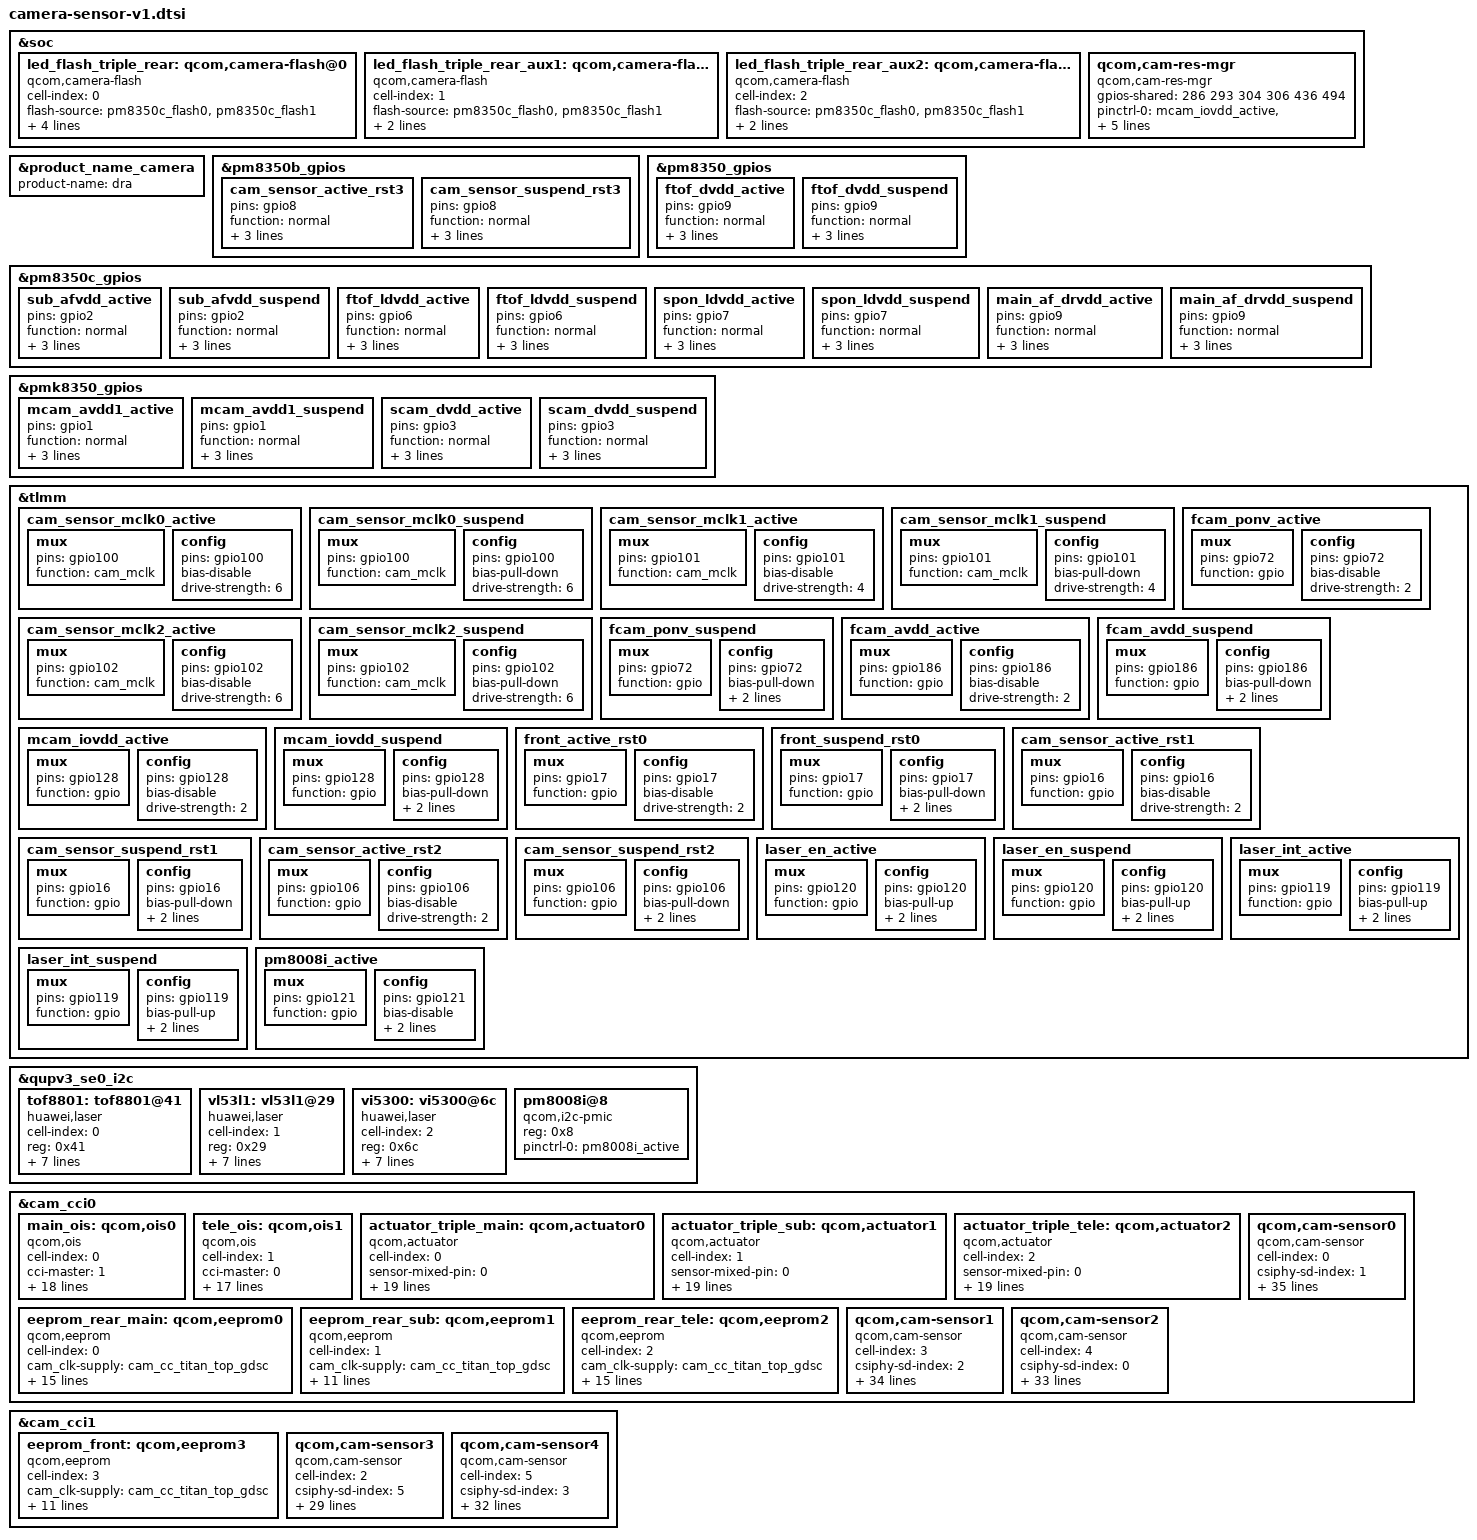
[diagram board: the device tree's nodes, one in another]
#include <dt-bindings/clock/qcom,camcc-lahaina.h>

&soc {
	led_flash_triple_rear: qcom,camera-flash@0 {
		cell-index = <0>;
		compatible = "qcom,camera-flash";
		flash-source = <&pm8350c_flash0 &pm8350c_flash1>;
		torch-source = <&pm8350c_torch0 &pm8350c_torch1>;
		switch-source = <&pm8350c_switch2>;
		torch-light-num = <0 1>;
		torch-light-name = "torch-light0", "torch-light1";
		status = "ok";
	};

	led_flash_triple_rear_aux1: qcom,camera-flash@1 {
		cell-index = <1>;
		compatible = "qcom,camera-flash";
		flash-source = <&pm8350c_flash0 &pm8350c_flash1>;
		torch-source = <&pm8350c_torch0 &pm8350c_torch1>;
		switch-source = <&pm8350c_switch2>;
		status = "ok";
	};

	led_flash_triple_rear_aux2: qcom,camera-flash@2 {
		cell-index = <2>;
		compatible = "qcom,camera-flash";
		flash-source = <&pm8350c_flash0 &pm8350c_flash1>;
		torch-source = <&pm8350c_torch0 &pm8350c_torch1>;
		switch-source = <&pm8350c_switch2>;
		status = "ok";
	};

	qcom,cam-res-mgr {
		compatible = "qcom,cam-res-mgr";
		status = "ok";
		gpios-shared = <286 293 304 306 436 494>;
		pinctrl-names = "cam_active", "cam_suspend";
		pinctrl-0 = <&mcam_iovdd_active
					&front_active_rst0
					&fcam_avdd_active
					&mcam_avdd1_active>;
		pinctrl-1 = <&mcam_iovdd_suspend
					&front_suspend_rst0
					&fcam_avdd_suspend
					&mcam_avdd1_suspend>;
	};
};

&product_name_camera {
    product-name = "dra";
};

&pm8350b_gpios {
	cam_sensor_active_rst3: cam_sensor_active_rst3 {
		pins = "gpio8";
		function = "normal";
		bias-disable;
		output-high;
		power-source = <0>;
	};
	cam_sensor_suspend_rst3: cam_sensor_suspend_rst3 {
		pins = "gpio8";
		function = "normal";
		bias-disable;
		output-low;
		power-source = <0>;
	};
};

&pm8350_gpios {
	ftof_dvdd_active: ftof_dvdd_active {
		pins = "gpio9";
		function = "normal";
		bias-disable;
		output-high;
		power-source = <0>;
	};
	ftof_dvdd_suspend: ftof_dvdd_suspend {
		pins = "gpio9";
		function = "normal";
		bias-disable;
		output-low;
		power-source = <0>;
	};
};

&pm8350c_gpios {
	sub_afvdd_active: sub_afvdd_active {
		pins = "gpio2";
		function = "normal";
		bias-disable;
		output-high;
		power-source = <0>;
	};
	sub_afvdd_suspend: sub_afvdd_suspend {
		pins = "gpio2";
		function = "normal";
		bias-disable;
		output-low;
		power-source = <0>;
	};
	ftof_ldvdd_active: ftof_ldvdd_active {
		pins = "gpio6";
		function = "normal";
		bias-disable;
		output-high;
		power-source = <0>;
	};
	ftof_ldvdd_suspend: ftof_ldvdd_suspend {
		pins = "gpio6";
		function = "normal";
		bias-disable;
		output-low;
		power-source = <0>;
	};
	spon_ldvdd_active: spon_ldvdd_active {
		pins = "gpio7";
		function = "normal";
		bias-disable;
		output-high;
		power-source = <0>;
	};
	spon_ldvdd_suspend: spon_ldvdd_suspend {
		pins = "gpio7";
		function = "normal";
		bias-disable;
		output-low;
		power-source = <0>;
	};
	main_af_drvdd_active: main_af_drvdd_active {
		pins = "gpio9";
		function = "normal";
		bias-disable;
		output-high;
		power-source = <0>;
	};
	main_af_drvdd_suspend: main_af_drvdd_suspend {
		pins = "gpio9";
		function = "normal";
		bias-disable;
		output-low;
		power-source = <0>;
	};
};

&pmk8350_gpios {
	mcam_avdd1_active: mcam_avdd1_active {
		pins = "gpio1";
		function = "normal";
		bias-disable;
		output-high;
		power-source = <0>;
	};
	mcam_avdd1_suspend: mcam_avdd1_suspend {
		pins = "gpio1";
		function = "normal";
		bias-disable;
		output-low;
		power-source = <0>;
	};

	scam_dvdd_active: scam_dvdd_active {
		pins = "gpio3";
		function = "normal";
		bias-disable;
		output-high;
		power-source = <0>;
	};
	scam_dvdd_suspend: scam_dvdd_suspend {
		pins = "gpio3";
		function = "normal";
		bias-disable;
		output-low;
		power-source = <0>;
	};
};

&tlmm {
	cam_sensor_mclk0_active: cam_sensor_mclk0_active {
		/* MCLK0 */
		mux {
			pins = "gpio100";
			function = "cam_mclk";
		};

		config {
			pins = "gpio100";
			bias-disable; /* No PULL */
			drive-strength = <6>; /* 2 MA */
		};
	};

	cam_sensor_mclk0_suspend: cam_sensor_mclk0_suspend {
		/* MCLK0 */
		mux {
			pins = "gpio100";
			function = "cam_mclk";
		};

		config {
			pins = "gpio100";
			bias-pull-down; /* PULL DOWN */
			drive-strength = <6>; /* 2 MA */
		};
	};

	cam_sensor_mclk1_active: cam_sensor_mclk1_active {
		/* MCLK1 */
		mux {
			pins = "gpio101";
			function = "cam_mclk";
		};

		config {
			pins = "gpio101";
			bias-disable; /* No PULL */
			drive-strength = <4>; /* 2 MA */
		};
	};

	cam_sensor_mclk1_suspend: cam_sensor_mclk1_suspend {
		/* MCLK1 */
		mux {
			pins = "gpio101";
			function = "cam_mclk";
		};

		config {
			pins = "gpio101";
			bias-pull-down; /* PULL DOWN */
			drive-strength = <4>; /* 2 MA */
		};
	};

	cam_sensor_mclk2_active: cam_sensor_mclk2_active {
		/* MCLK2 */
		mux {
			pins = "gpio102";
			function = "cam_mclk";
		};

		config {
			pins = "gpio102";
			bias-disable; /* No PULL */
			drive-strength = <6>; /* 2 MA */
		};
	};

	cam_sensor_mclk2_suspend: cam_sensor_mclk2_suspend {
		/* MCLK2 */
		mux {
			pins = "gpio102";
			function = "cam_mclk";
		};

		config {
			pins = "gpio102";
			bias-pull-down; /* PULL DOWN */
			drive-strength = <6>; /* 2 MA */
		};
	};

	fcam_ponv_active: fcam_ponv_active {
		/* fcam ponv */
		mux {
			pins = "gpio72";
			function = "gpio";
		};

		config {
			pins = "gpio72";
			bias-disable; /* No PULL */
			drive-strength = <2>; /* 2 MA */
		};
	};

	fcam_ponv_suspend: fcam_ponv_suspend {
		/* fcam ponv */
		mux {
			pins = "gpio72";
			function = "gpio";
		};

		config {
			pins = "gpio72";
			bias-pull-down; /* PULL DOWN */
			drive-strength = <2>; /* 2 MA */
			output-low;
		};
	};

	fcam_avdd_active: fcam_avdd_active {
		/* fcam avdd */
		mux {
			pins = "gpio186";
			function = "gpio";
		};

		config {
			pins = "gpio186";
			bias-disable; /* No PULL */
			drive-strength = <2>; /* 2 MA */
		};
	};
	fcam_avdd_suspend: fcam_avdd_suspend {
		/* fcam avdd */
		mux {
			pins = "gpio186";
			function = "gpio";
		};

		config {
			pins = "gpio186";
			bias-pull-down; /* PULL DOWN */
			drive-strength = <2>; /* 2 MA */
			output-low;
		};
	};

	mcam_iovdd_active: mcam_iovdd_active {
		mux {
			pins = "gpio128";
			function = "gpio";
		};

		config {
			pins = "gpio128";
			bias-disable; /* No PULL */
			drive-strength = <2>; /* 2 MA */
		};
	};
	mcam_iovdd_suspend: mcam_iovdd_suspend {
		mux {
			pins = "gpio128";
			function = "gpio";
		};

		config {
			pins = "gpio128";
			bias-pull-down; /* PULL DOWN */
			drive-strength = <2>; /* 2 MA */
			output-low;
		};
	};

	front_active_rst0: front_active_rst0 {
		/* RESET 0 */
		mux {
			pins = "gpio17";
			function = "gpio";
		};

		config {
			pins = "gpio17";
			bias-disable; /* No PULL */
			drive-strength = <2>; /* 2 MA */
		};
	};

	front_suspend_rst0: front_suspend_rst0 {
		/* RESET 0 */
		mux {
			pins = "gpio17";
			function = "gpio";
		};

		config {
			pins = "gpio17";
			bias-pull-down; /* PULL DOWN */
			drive-strength = <2>; /* 2 MA */
			output-low;
		};
	};

	cam_sensor_active_rst1: cam_sensor_active_rst1 {
		/* RESET 1 */
		mux {
			pins = "gpio16";
			function = "gpio";
		};

		config {
			pins = "gpio16";
			bias-disable; /* No PULL */
			drive-strength = <2>; /* 2 MA */
		};
	};
	cam_sensor_suspend_rst1: cam_sensor_suspend_rst1 {
		/* RESET 1 */
		mux {
			pins = "gpio16";
			function = "gpio";
		};

		config {
			pins = "gpio16";
			bias-pull-down; /* PULL DOWN */
			drive-strength = <2>; /* 2 MA */
			output-low;
		};
	};

	cam_sensor_active_rst2: cam_sensor_active_rst2 {
		/* RESET 2 */
		mux {
			pins = "gpio106";
			function = "gpio";
		};

		config {
			pins = "gpio106";
			bias-disable; /* No PULL */
			drive-strength = <2>; /* 2 MA */
		};
	};
	cam_sensor_suspend_rst2: cam_sensor_suspend_rst2 {
		/* RESET 2 */
		mux {
			pins = "gpio106";
			function = "gpio";
		};

		config {
			pins = "gpio106";
			bias-pull-down; /* PULL DOWN */
			drive-strength = <2>; /* 2 MA */
			output-low;
		};
	};

	laser_en_active: laser_en_active {
		/* laser en pin */
		mux {
			pins = "gpio120";
			function = "gpio";
		};

		config {
			pins = "gpio120";
			bias-pull-up; /* PULL UP */
			drive-strength = <2>; /* 2 MA */
			input-enable;
		};
	};

	laser_en_suspend: laser_en_suspend {
		/* laser en pin */
		mux {
			pins = "gpio120";
			function = "gpio";
		};

		config {
			pins = "gpio120";
			bias-pull-up; /* PULL UP */
			drive-strength = <2>; /* 2 MA */
			input-enable;
		};
	};

	laser_int_active: laser_int_active {
		/* laser int pin */
		mux {
			pins = "gpio119";
			function = "gpio";
		};

		config {
			pins = "gpio119";
			bias-pull-up; /* PULL UP */
			drive-strength = <2>; /* 2 MA */
			input-enable;
		};
	};

	laser_int_suspend: laser_int_suspend {
		/* laser int pin */
		mux {
			pins = "gpio119";
			function = "gpio";
		};

		config {
			pins = "gpio119";
			bias-pull-up; /* PULL UP */
			drive-strength = <2>; /* 2 MA */
			input-enable;
		};
	};

	pm8008i_active: pm8008i_active {
		mux {
			pins = "gpio121";
			function = "gpio";
		};

		config {
			pins = "gpio121";
			bias-disable;
			output-low;
			drive-strength = <2>;
		};
	};
};

/* laser */
&qupv3_se0_i2c {
	status = "ok";
	#address-cells = <1>;
	#size-cells = <0>;

	tof8801: tof8801@41 {
		cell-index = <0>;
		compatible = "huawei,laser";
		reg = <0x41>;
		vdd_ana-supply = <&pm8350_l7>;
		gpios = <&tlmm 120 0>,
			<&tlmm 119 0>;
		pinctrl-names = "laser_int_active", "laser_en_active";
		pinctrl-0 = <&laser_int_active>;
		pinctrl-1 = <&laser_en_active>;
		gpio-req-tbl-num = <0>;
		gpio-req-tbl-flags = <0>;
		gpio-req-tbl-label = "CAM_VAF0";
		status = "ok";
	};

	vl53l1: vl53l1@29 {
		cell-index = <1>;
		compatible = "huawei,laser";
		reg = <0x29>;
		vdd_ana-supply = <&pm8350_l7>;
		gpios = <&tlmm 120 0>,
			<&tlmm 119 0>;
		pinctrl-names = "laser_int_active", "laser_en_active";
		pinctrl-0 = <&laser_int_active>;
		pinctrl-1 = <&laser_en_active>;
		gpio-req-tbl-num = <0>;
		gpio-req-tbl-flags = <0>;
		gpio-req-tbl-label = "CAM_VAF0";
		status = "ok";
	};

	vi5300: vi5300@6c {
		cell-index = <2>;
		compatible = "huawei,laser";
		reg = <0x6c>;
		vdd_ana-supply = <&pm8350_l7>;
		gpios = <&tlmm 120 0>,
			<&tlmm 119 0>;
		pinctrl-names = "laser_int_active", "laser_en_active";
		pinctrl-0 = <&laser_int_active>;
		pinctrl-1 = <&laser_en_active>;
		gpio-req-tbl-num = <0>;
		gpio-req-tbl-flags = <0>;
		gpio-req-tbl-label = "CAM_VAF0";
		status = "ok";
	};

	pm8008i@8 {
		compatible = "qcom,i2c-pmic";
		reg = <0x8>;
		#address-cells = <1>;
		#size-cells = <0>;

		pinctrl-names = "default";
		pinctrl-0 = <&pm8008i_active>;

	};
};

&cam_cci0 {
	main_ois: qcom,ois0 {
		cell-index = <0>;
		compatible = "qcom,ois";
		cci-master = <1>;
		cam_clk-supply = <&cam_cc_titan_top_gdsc>;
		regulator-names = "cam_clk";
		rgltr-cntrl-support;
		rgltr-min-voltage = <0>;
		rgltr-max-voltage = <0>;
		rgltr-load-current = <0>;
		gpio-no-mux = <0>;
		pinctrl-names = "cam_default", "cam_suspend";
		pinctrl-0 = <&main_af_drvdd_active>;
		pinctrl-1 = <&main_af_drvdd_suspend>;
		gpios = <&pm8350c_gpios 9 0>,
			<&tlmm 121 0>;
		gpio-mixed1 = <0>;
		gpio-mixed2 = <1>;
		gpio-req-tbl-num = <0 1>;
		gpio-req-tbl-flags = <0 0>;
		gpio-req-tbl-label = "DRVDD",
					"AFVDD";
		status = "ok";
		clocks = <&clock_camcc CAM_CC_MCLK0_CLK>;
		clock-names = "cam_clk";
		clock-cntl-level = "nominal";
		clock-rates = <19200000>;
	};

	tele_ois: qcom,ois1 {
		cell-index = <1>;
		compatible = "qcom,ois";
		cci-master = <0>;
		cam_clk-supply = <&cam_cc_titan_top_gdsc>;
		regulator-names = "cam_clk";
		rgltr-cntrl-support;
		rgltr-min-voltage = <0>;
		rgltr-max-voltage = <0>;
		rgltr-load-current = <0>;
		gpio-no-mux = <0>;
		pinctrl-names = "cam_default", "cam_suspend";
		pinctrl-0 = <&main_af_drvdd_active>;
		pinctrl-1 = <&main_af_drvdd_suspend>;
		gpios = <&pm8350c_gpios 9 0>,
				<&tlmm 121 0>;
		gpio-mixed2 = <1>;
		gpio-req-tbl-num = <0 1>;
		gpio-req-tbl-flags = <0 0>;
		gpio-req-tbl-label = "DRVDD", "MOIS-AFVDD";
		status = "ok";
		clocks = <&clock_camcc CAM_CC_MCLK0_CLK>;
		clock-names = "cam_clk";
		clock-cntl-level = "nominal";
		clock-rates = <19200000>;
	};

	actuator_triple_main: qcom,actuator0 {
		cell-index = <0>;
		compatible = "qcom,actuator";
		sensor-mixed-pin = <0>;
		cam_clk-supply = <&cam_cc_titan_top_gdsc>;
		regulator-names = "cam_clk";
		rgltr-cntrl-support;
		rgltr-min-voltage = <0>;
		rgltr-max-voltage = <0>;
		rgltr-load-current = <0>;
		gpio-no-mux = <0>;
		pinctrl-names = "cam_default", "cam_suspend";
		pinctrl-0 = <&main_af_drvdd_active>;
		pinctrl-1 = <&main_af_drvdd_suspend>;
		gpios = <&pm8350c_gpios 9 0>,
			<&tlmm 121 0>;
		gpio-mixed1 = <0>;
		gpio-mixed2 = <1>;
		gpio-req-tbl-num = <0 1>;
		gpio-req-tbl-flags = <0 0>;
		gpio-req-tbl-label = "DRVDD",
					"AFVDD";
		cci-master = <1>;
		status = "ok";
		clocks = <&clock_camcc CAM_CC_MCLK0_CLK>;
		clock-names = "cam_clk";
		clock-cntl-level = "nominal";
		clock-rates = <19200000>;
	};

	actuator_triple_sub: qcom,actuator1 {
		cell-index = <1>;
		compatible = "qcom,actuator";
		sensor-mixed-pin = <0>;
		cam_clk-supply = <&cam_cc_titan_top_gdsc>;
		regulator-names = "cam_clk";
		rgltr-cntrl-support;
		5v_boost_support;
		rgltr-min-voltage = <0>;
		rgltr-max-voltage = <0>;
		rgltr-load-current = <0>;
		gpio-no-mux = <0>;
		pinctrl-names = "cam_default", "cam_suspend";
		pinctrl-0 = <&sub_afvdd_active>;
		pinctrl-1 = <&sub_afvdd_suspend>;
		gpios = <&pm8350c_gpios 2 0>;
		gpio-mixed1 = <0>;
		gpio-req-tbl-num = <0>;
		gpio-req-tbl-flags = <0>;
		gpio-req-tbl-label = "AFVDD";
		cci-master = <0>;
		status = "ok";
		clocks = <&clock_camcc CAM_CC_MCLK1_CLK>;
		clock-names = "cam_clk";
		clock-cntl-level = "nominal";
		clock-rates = <19200000>;
	};

	actuator_triple_tele: qcom,actuator2 {
		cell-index = <2>;
		compatible = "qcom,actuator";
		sensor-mixed-pin = <0>;
		cam_clk-supply = <&cam_cc_titan_top_gdsc>;
		regulator-names = "cam_clk";
		rgltr-cntrl-support;
		5v_boost_support;
		rgltr-min-voltage = <0>;
		rgltr-max-voltage = <0>;
		rgltr-load-current = <0>;
		gpio-no-mux = <0>;
		pinctrl-names = "cam_default", "cam_suspend";
		pinctrl-0 = <&sub_afvdd_active>;
		pinctrl-1 = <&sub_afvdd_suspend>;
		gpios = <&pm8350c_gpios 2 0>;
		gpio-mixed1 = <0>;
		gpio-req-tbl-num = <0>;
		gpio-req-tbl-flags = <0>;
		gpio-req-tbl-label = "AFVDD";
		cci-master = <0>;
		status = "ok";
		clocks = <&clock_camcc CAM_CC_MCLK0_CLK>;
		clock-names = "cam_clk";
		clock-cntl-level = "nominal";
		clock-rates = <19200000>;
	};

	eeprom_rear_main: qcom,eeprom0 {
		cell-index = <0>;
		compatible = "qcom,eeprom";
		cam_clk-supply = <&cam_cc_titan_top_gdsc>;
		regulator-names = "cam_clk";
		rgltr-cntrl-support;
		rgltr-min-voltage = <0>;
		rgltr-max-voltage = <0>;
		rgltr-load-current = <0>;
		gpio-no-mux = <0>;
		gpios = <&tlmm 128 0>;
		gpio-mixed1 = <0>;
		gpio-req-tbl-num = <0>;
		gpio-req-tbl-flags = <0>;
		gpio-req-tbl-label = "CAM_VIO";
		cci-master = <1>;
		status = "ok";
		clocks = <&clock_camcc CAM_CC_MCLK0_CLK>;
		clock-names = "cam_clk";
		clock-cntl-level = "nominal";
		clock-rates = <19200000>;
	};

	eeprom_rear_sub: qcom,eeprom1 {
		cell-index = <1>;
		compatible = "qcom,eeprom";
		cam_clk-supply = <&cam_cc_titan_top_gdsc>;
		cam_vio-supply = <&pm8350c_l8>;
		regulator-names = "cam_clk", "cam_vio";
		rgltr-cntrl-support;
		rgltr-min-voltage = <0 1800000>;
		rgltr-max-voltage = <0 1800000>;
		rgltr-load-current = <0 3000>;
		gpio-no-mux = <0>;
		cci-master = <0>;
		status = "ok";
		clocks = <&clock_camcc CAM_CC_MCLK1_CLK>;
		clock-names = "cam_clk";
		clock-cntl-level = "nominal";
		clock-rates = <19200000>;
	};

	eeprom_rear_tele: qcom,eeprom2 {
		cell-index = <2>;
		compatible = "qcom,eeprom";
		cam_clk-supply = <&cam_cc_titan_top_gdsc>;
		regulator-names = "cam_clk";
		rgltr-cntrl-support;
		rgltr-min-voltage = <0>;
		rgltr-max-voltage = <0>;
		rgltr-load-current = <0>;
		gpio-no-mux = <0>;
		gpios = <&tlmm 128 0>;
		gpio-mixed1 = <0>;
		gpio-req-tbl-num = <0>;
		gpio-req-tbl-flags = <0>;
		gpio-req-tbl-label = "CAM_VIO";
		cci-master = <0>;
		status = "ok";
		clocks = <&clock_camcc CAM_CC_MCLK0_CLK>;
		clock-names = "cam_clk";
		clock-cntl-level = "nominal";
		clock-rates = <19200000>;
	};

	/* back main sensor */
	qcom,cam-sensor0 {
		cell-index = <0>;
		compatible = "qcom,cam-sensor";
		csiphy-sd-index = <1>;
		sensor-mixed-pin = <0>;
		sensor-position-roll = <90>;
		sensor-position-pitch = <0>;
		sensor-position-yaw = <180>;
		eeprom-src = <&eeprom_rear_main>;
		actuator-src = <&actuator_triple_main>;
		led-flash-src = <&led_flash_triple_rear>;
		ois-src  = <&main_ois>;
		cam_clk-supply = <&cam_cc_titan_top_gdsc>;
		cam_vdig-supply = <&pm8350c_l11>;
		regulator-names = "cam_clk", "cam_vdig";
		rgltr-cntrl-support;
		5v_boost_support;
		rgltr-min-voltage = <0 2960000>;
		rgltr-max-voltage = <0 3000000>;
		rgltr-load-current = <0 3000>;  //zhangzhijia
		gpio-no-mux = <0>;
		pinctrl-names = "cam_default", "cam_suspend";
		pinctrl-0 = <&cam_sensor_mclk0_active
				&cam_sensor_active_rst1>;
		pinctrl-1 = <&cam_sensor_mclk0_suspend
				&cam_sensor_suspend_rst1>;
		gpios = <&tlmm 100 0>,
			<&tlmm 16 0>,
			<&tlmm 128 0>,
			<&pmk8350_gpios 1 0>,
			<&tlmm 121 0>;
		gpio-reset = <1>;
		gpio-mixed1 = <2>;
		gpio-mixed2 = <3>;
		gpio-mixed3 = <4>;
		gpio-req-tbl-num = <0 1 2 3 4>;
		gpio-req-tbl-flags = <1 0 0 0 0>;
		gpio-req-tbl-label = "CAM_MCLK0",
					"CAM_RESET",
					"CAM_IOVDD",
					"CAM_LDAVDD",
					"AFVDD";
		cci-master = <1>;
		status = "ok";
		clocks = <&clock_camcc CAM_CC_MCLK0_CLK>;
		clock-names = "cam_clk";
		clock-cntl-level = "nominal";
		clock-rates = <19200000>;
	};
	/* back wide sensor */
	qcom,cam-sensor1 {
		cell-index = <3>;
		compatible = "qcom,cam-sensor";
		csiphy-sd-index = <2>;
		sensor-mixed-pin = <0>;
		sensor-position-roll = <90>;
		sensor-position-pitch = <0>;
		sensor-position-yaw = <180>;
		actuator-src = <&actuator_triple_sub>;
		eeprom-src = <&eeprom_rear_sub>;
		led-flash-src = <&led_flash_triple_rear_aux1>;
		cam_clk-supply = <&cam_cc_titan_top_gdsc>;
		cam_vio-supply = <&pm8350c_l8>;
		regulator-names = "cam_clk", "cam_vio";
		rgltr-cntrl-support;
		rgltr-min-voltage = <0 1800000>;
		rgltr-max-voltage = <0 1800000>;
		rgltr-load-current = <0 3000>;
		gpio-no-mux = <0>;
		pinctrl-names = "cam_default", "cam_suspend";
		pinctrl-0 = <&cam_sensor_mclk1_active
				&scam_dvdd_active
				&spon_ldvdd_active
				&cam_sensor_active_rst2>;
		pinctrl-1 = <&cam_sensor_mclk1_suspend
				&scam_dvdd_suspend
				&spon_ldvdd_suspend
				&cam_sensor_suspend_rst2>;
		gpios = <&tlmm 101 0>,
			<&tlmm 106 0>,
			<&pmk8350_gpios 3 0>,
			<&pm8350c_gpios 7 0>;
		gpio-reset = <1>;
		gpio-mixed1 = <2>;
		gpio-mixed2 = <3>;
		gpio-req-tbl-num = <0 1 2 3>;
		gpio-req-tbl-flags = <1 0 0 0>;
		gpio-req-tbl-label = "CAMIF_MCLK1",
					"CAM_RESET2",
					"CAM_DVDD",
					"CAM_PONV";
		cci-master = <0>;
		status = "ok";
		clocks = <&clock_camcc CAM_CC_MCLK1_CLK>;
		clock-names = "cam_clk";
		clock-cntl-level = "nominal";
		clock-rates = <19200000>;
	};

	/* back tele sensor */
	qcom,cam-sensor2 {
		cell-index = <4>;
		compatible = "qcom,cam-sensor";
		csiphy-sd-index = <0>;
		sensor-mixed-pin = <0>;
		sensor-position-roll = <90>;
		sensor-position-pitch = <0>;
		sensor-position-yaw = <180>;
		actuator-src = <&actuator_triple_tele>;
		eeprom-src = <&eeprom_rear_tele>;
		ois-src  = <&tele_ois>;
		led-flash-src = <&led_flash_triple_rear_aux2>;
		cam_clk-supply = <&cam_cc_titan_top_gdsc>;
		regulator-names = "cam_clk";
		rgltr-cntrl-support;
		rgltr-min-voltage = <0>;
		rgltr-max-voltage = <0>;
		rgltr-load-current = <0>;
		gpio-no-mux = <0>;
		pinctrl-names = "cam_default", "cam_suspend";
		pinctrl-0 = <&cam_sensor_mclk0_active
				&cam_sensor_active_rst3>;
		pinctrl-1 = <&cam_sensor_mclk0_suspend
				&cam_sensor_suspend_rst3>;
		gpios = <&tlmm 100 0>,
			<&pm8350b_gpios 8 0>,
			<&tlmm 128 0>,
			<&tlmm 186 0>,
			<&pmk8350_gpios 1 0>;
		gpio-reset = <1>;
		gpio-mixed1 = <2>;
		gpio-mixed2 = <3>;
		gpio-mixed3 = <4>;
		gpio-req-tbl-num = <0 1 2 3 4>;
		gpio-req-tbl-flags = <1 0 0 0 0>;
		gpio-req-tbl-label = "CAMIF_MCLK2",
					"CAM_RESET3",
					"CAM_IOVDD",
					"CAM_AVDD",
					"CAM_DVDD";
		cci-master = <0>;
		status = "ok";
		clocks = <&clock_camcc CAM_CC_MCLK0_CLK>;
		clock-names = "cam_clk";
		clock-cntl-level = "nominal";
		clock-rates = <19200000>;
	};
};

&cam_cci1 {
	eeprom_front: qcom,eeprom3 {
		cell-index = <3>;
		compatible = "qcom,eeprom";
		cam_clk-supply = <&cam_cc_titan_top_gdsc>;
		cam_vio-supply = <&pm8350c_l8>;
		regulator-names = "cam_clk", "cam_vio";
		rgltr-cntrl-support;
		rgltr-min-voltage = <0 1800000>;
		rgltr-max-voltage = <0 1800000>;
		rgltr-load-current = <0 3000>;
		gpio-no-mux = <0>;
		cci-master = <1>;
		status = "ok";
		clocks = <&clock_camcc CAM_CC_MCLK1_CLK>;
		clock-names = "cam_clk";
		clock-cntl-level = "nominal";
		clock-rates = <19200000>;
	};
	/* front main sensor */
	qcom,cam-sensor3 {
		cell-index = <2>;
		compatible = "qcom,cam-sensor";
		csiphy-sd-index = <5>;
		sensor-mixed-pin = <0>;
		sensor-position-roll = <270>;
		sensor-position-pitch = <0>;
		sensor-position-yaw = <0>;
		/* actuator-src = <&actuator_front>; */
		eeprom-src = <&eeprom_front>;
		cam_clk-supply = <&cam_cc_titan_top_gdsc>;
		cam_vio-supply = <&pm8350c_l8>;
		regulator-names = "cam_clk", "cam_vio";
		rgltr-cntrl-support;
		rgltr-min-voltage = <0 1800000>;
		rgltr-max-voltage = <0 1800000>;
		rgltr-load-current = <0 3000>;
		gpio-no-mux = <0>;
		pinctrl-names = "cam_default", "cam_suspend";
		pinctrl-0 = <&cam_sensor_mclk1_active
				&fcam_ponv_active>;
		pinctrl-1 = <&cam_sensor_mclk1_suspend
				&fcam_ponv_suspend>;
		gpios = <&tlmm 101 0>,
			<&tlmm 17 0>,
			<&tlmm 186 0>,
			<&tlmm 72 0>;
		gpio-reset = <1>;
		gpio-mixed1 = <2>;
		gpio-mixed2 = <3>;
		gpio-req-tbl-num = <0 1 2 3>;
		gpio-req-tbl-flags = <1 0 0 0>;
		gpio-req-tbl-label = "CAMIF_MCLK2",
					"CAM_RESET2",
					"CAM_AVDD",
					"CAM_PONV";
		cci-master = <1>;
		status = "ok";
		clocks = <&clock_camcc CAM_CC_MCLK1_CLK>;
		clock-names = "cam_clk";
		clock-cntl-level = "nominal";
		clock-rates = <19200000>;
	};

	/* front tof sensor */
	qcom,cam-sensor4 {
		cell-index = <5>;
		compatible = "qcom,cam-sensor";
		csiphy-sd-index = <3>;
		sensor-mixed-pin = <0>;
		sensor-position-roll = <90>;
		sensor-position-pitch = <0>;
		sensor-position-yaw = <0>;
		/* eeprom-src = <&eeprom_rear_tele>; */
		cam_clk-supply = <&cam_cc_titan_top_gdsc>;
		regulator-names = "cam_clk";
		rgltr-cntrl-support;
		5v_boost_support;
		rgltr-min-voltage = <0>;
		rgltr-max-voltage = <0>;
		rgltr-load-current = <0>;
		gpio-no-mux = <0>;
		pinctrl-names = "cam_default", "cam_suspend";
		pinctrl-0 = <&cam_sensor_mclk2_active
					&ftof_dvdd_active
					&ftof_ldvdd_active>;
		pinctrl-1 = <&cam_sensor_mclk2_suspend
					&ftof_dvdd_suspend
					&ftof_ldvdd_suspend>;
		gpios = <&tlmm 102 0>,
			<&pm8350_gpios 8 0>,
			<&tlmm 128 0>,
			<&pm8350c_gpios 6 0>,
			<&pmk8350_gpios 1 0>,
			<&pm8350_gpios 9 0>;
		gpio-reset = <1>;
		gpio-mixed1 = <2>;
		gpio-mixed2 = <3>;
		gpio-mixed3 = <4>;
		gpio-mixed4 = <5>;
		gpio-req-tbl-num = <0 1 2 3 4 5>;
		gpio-req-tbl-flags = <1 0 0 0 0 0>;
		gpio-req-tbl-label = "CAMIF_MCLK2",
					"CAM_RESET3",
					"CAM_IOVDD",
					"CAM_LDVDD",
					"CAM_AVDD",
					"CAM_DVDD";
		cci-master = <0>;
		status = "ok";
		clocks = <&clock_camcc CAM_CC_MCLK2_CLK>;
		clock-names = "cam_clk";
		clock-cntl-level = "nominal";
		clock-rates = <19200000>;
	};
};
